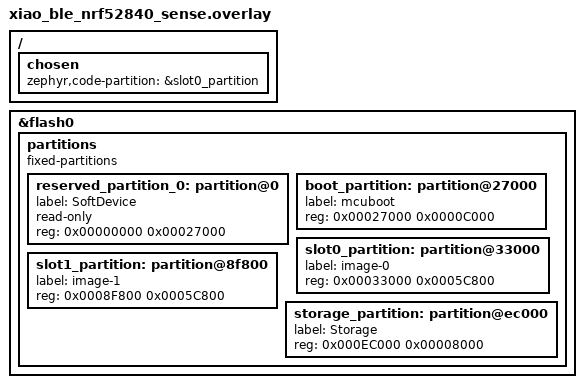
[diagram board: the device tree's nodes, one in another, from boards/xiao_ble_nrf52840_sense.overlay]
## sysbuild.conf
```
#
# Builds MCUboot as a child image so blink can be updated over BLE (OTA)
# instead of only via UF2 drag-and-drop. See apps/blink/pm_static.yml for the
# partition layout this requires.
#
SB_CONFIG_BOOTLOADER_MCUBOOT=y
```

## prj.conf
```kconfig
# Phase 0 bring-up: LED blink.
#
# Deliberately minimal — no console, no USB, no sensor drivers. If this does not
# blink, the fault is in the toolchain, the flash path or the board, not in our
# code. Console and IMU come next, one at a time.

CONFIG_GPIO=y

# Repair the hardware reset line.
#
# This board arrived with UICR->PSELRESET unconfigured, which makes the RST
# button inert: 90 s of double-tapping produced no USB re-enumeration at all.
# Without a working RST there is no way back into the UF2 bootloader, because
# Zephyr's CDC does not implement the 1200-baud touch that the previous
# (Arduino/CircuitPython) firmware did.
#
# With this set, modules/hal/nordic/nrfx/mdk/system_nrf52.c (~line 344) checks
# PSELRESET[0]/[1] at boot, and if they are not Connected writes RESET_PIN to
# both and issues NVIC_SystemReset(). The write is guarded, so it happens once
# and is a no-op on every later boot.
#
# Kconfig is marked DEPRECATED in favour of `&uicr { gpio-as-nreset; }`, which
# this board's DTS already has — but that did not translate into the generated
# .config on NCS v3.1.1, and the built hex contained no UICR segment. The
# deprecated symbol is the mechanism that demonstrably works here, so it is
# used deliberately. Expect a deprecation warning at build time.
CONFIG_GPIO_AS_PINRESET=y

# BLE OTA. NCS's own fragment (the same one Nordic's Thingy:53 DFU sample
# uses) - selects MCUmgr, the image manager and flash map for us rather than
# hand-assembling those. See apps/blink/sysbuild.conf for the MCUboot side and
# apps/blink/boards/xiao_ble_nrf52840_sense.overlay for the partition layout
# both of this depend on.
#
# The fragment only *depends on* BT_PERIPHERAL, it does not select it - a
# first attempt without these two lines built clean but silently produced a
# non-BLE blink (Kconfig warned "assigned 'y' but got 'n'": unsatisfied
# BT_PERIPHERAL dependency), so they are required, not redundant.
CONFIG_BT=y
CONFIG_BT_PERIPHERAL=y
CONFIG_NCS_SAMPLE_MCUMGR_BT_OTA_DFU=y
CONFIG_BT_DEVICE_NAME="falldetect-blink"
```

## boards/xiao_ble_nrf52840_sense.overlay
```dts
/*
 * BLE OTA layout: splits the board's stock 788 KB "Application" partition
 * (zephyr/dts/vendor/nordic/nrf52840_partition_uf2_sdv7.dtsi, included by
 * zephyr/boards/seeed/xiao_ble/xiao_ble_common.dtsi) into MCUboot + two
 * update slots.
 *
 * The three regions the Adafruit UF2 bootloader itself owns - SoftDevice
 * (0x0-0x27000), Storage (0xec000-0xf4000), and its own code at the top of
 * flash (0xf4000-0x100000, previously labelled "boot_partition"/"UF2" in the
 * stock dtsi) - keep their stock addresses and sizes, and are simply left
 * out of this partitions node. Nothing here writes to that top-of-flash
 * region, so double-tap-RST UF2 recovery still works for this entire span
 * even if a bad OTA image is ever written to slot0/slot1.
 *
 * Must stay identical to sysbuild/mcuboot.overlay - that file gives MCUboot
 * itself the same view of these partitions; this one gives it to the app.
 *
 * Math (hand-verified, fills the stock 0x27000-0xec000 span exactly):
 *   0x27000-0x33000  boot_partition   MCUboot itself       48 KB
 *   0x33000-0x8f800  slot0_partition  primary app slot    370 KB
 *   0x8f800-0xec000  slot1_partition  secondary/OTA slot  370 KB
 */

&flash0 {
	/delete-node/ partitions;

	partitions {
		compatible = "fixed-partitions";
		#address-cells = <1>;
		#size-cells = <1>;

		reserved_partition_0: partition@0 {
			label = "SoftDevice";
			read-only;
			reg = <0x00000000 0x00027000>;
		};

		boot_partition: partition@27000 {
			label = "mcuboot";
			reg = <0x00027000 0x0000C000>;
		};

		slot0_partition: partition@33000 {
			label = "image-0";
			reg = <0x00033000 0x0005C800>;
		};

		slot1_partition: partition@8f800 {
			label = "image-1";
			reg = <0x0008F800 0x0005C800>;
		};

		storage_partition: partition@ec000 {
			label = "Storage";
			reg = <0x000EC000 0x00008000>;
		};
	};
};

/*
 * Set directly for the same reason as sysbuild/mcuboot.overlay: the board's
 * stock chosen node points at the code_partition label this overlay just
 * deleted. The app runs from slot0, not from boot_partition (that's MCUboot's).
 */
/ {
	chosen {
		zephyr,code-partition = &slot0_partition;
	};
};
```

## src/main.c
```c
/*
 * Phase 0 bring-up: LED blink.
 *
 * Purpose: prove the toolchain, flash path and runtime on the XIAO nRF52840
 * Sense before any peripheral work begins. Nothing here is part of the fall
 * detector; it exists so that a later failure can be attributed to the code
 * under test rather than to the build environment.
 *
 * Execution context: LED loop runs on main thread only. BLE OTA (added on top
 * of the original blink-only scope) brings in the Bluetooth host's own
 * context for connected()/bt_ready() - both only ever call k_work_submit(),
 * never touch the LEDs or block, so the two contexts never share state.
 *
 * Board facts (Verified against
 * zephyr/boards/seeed/xiao_ble/xiao_ble_common.dtsi):
 *   led0 = Red   P0.26, active-low
 *   led1 = Green P0.30, active-low
 *   led2 = Blue  P0.06, active-low
 *
 * The active-low polarity is carried by the devicetree GPIO flags, so
 * gpio_pin_set_dt()/gpio_pin_toggle_dt() take logical levels here: "1" means
 * lit. Do not open-code the inversion.
 *
 * All three channels sit in one RGB package, so driving them together reads as
 * white. It will not be a neutral white: the three dies have different forward
 * voltages behind fixed series resistors, so expect a blue/violet cast.
 * Balancing the channels needs PWM duty control, not plain GPIO.
 */

#include <zephyr/kernel.h>
#include <zephyr/drivers/gpio.h>
#include <zephyr/bluetooth/bluetooth.h>
#include <zephyr/bluetooth/conn.h>
#include <zephyr/bluetooth/hci.h>
#include <zephyr/mgmt/mcumgr/transport/smp_bt.h>
#include <zephyr/dfu/mcuboot.h>

#define BLINK_PERIOD_MS 500U

/*
 * BLE OTA advertising. Enabling CONFIG_BT_PERIPHERAL and the MCUmgr BT
 * transport (apps/blink/prj.conf) only compiles the SMP GATT service in -
 * nothing calls bt_enable()/bt_le_adv_start() on its own, so without this the
 * radio never turns on. Pattern matches Zephyr's own reference
 * (samples/subsys/mgmt/mcumgr/smp_svr/src/bluetooth.c) rather than
 * hand-rolled advertising params.
 *
 * Execution context: bt_ready()/connected()/disconnected() run on the
 * Bluetooth host's own context, not main thread; advertise() is deferred onto
 * the system workqueue via k_work so nothing blocking happens in those
 * callbacks.
 */
static struct k_work advertise_work;

static const struct bt_data ad[] = {
	BT_DATA_BYTES(BT_DATA_FLAGS, (BT_LE_AD_GENERAL | BT_LE_AD_NO_BREDR)),
	BT_DATA_BYTES(BT_DATA_UUID128_ALL, SMP_BT_SVC_UUID_VAL),
};

static const struct bt_data sd[] = {
	BT_DATA(BT_DATA_NAME_COMPLETE, CONFIG_BT_DEVICE_NAME, sizeof(CONFIG_BT_DEVICE_NAME) - 1),
};

static void advertise(struct k_work *work)
{
	ARG_UNUSED(work);

	(void)bt_le_adv_start(BT_LE_ADV_CONN_FAST_1, ad, ARRAY_SIZE(ad), sd, ARRAY_SIZE(sd));
}

static void connected(struct bt_conn *conn, uint8_t err)
{
	ARG_UNUSED(conn);

	if (err != 0) {
		k_work_submit(&advertise_work);
	}
}

static void on_conn_recycled(void)
{
	k_work_submit(&advertise_work);
}

BT_CONN_CB_DEFINE(conn_callbacks) = {
	.connected = connected,
	.recycled = on_conn_recycled,
};

static void bt_ready(int err)
{
	if (err == 0) {
		k_work_submit(&advertise_work);
	}
}

static const struct gpio_dt_spec leds[] = {
	GPIO_DT_SPEC_GET(DT_ALIAS(led0), gpios), /* Red   */
	GPIO_DT_SPEC_GET(DT_ALIAS(led1), gpios), /* Green */
	GPIO_DT_SPEC_GET(DT_ALIAS(led2), gpios), /* Blue  */
};

int main(void)
{
	int err;
	bool lit = false;

	k_work_init(&advertise_work, advertise);
	err = bt_enable(bt_ready);
	if (err != 0) {
		return err;
	}

	for (size_t i = 0; i < ARRAY_SIZE(leds); i++) {
		if (!gpio_is_ready_dt(&leds[i])) {
			/* GPIO controller not ready: nothing further is meaningful. */
			return -ENODEV;
		}

		/* Start dark, so the first transition is visibly a change. */
		err = gpio_pin_configure_dt(&leds[i], GPIO_OUTPUT_INACTIVE);
		if (err != 0) {
			return err;
		}
	}

	/*
	 * MCUboot reverts to the previous image on the NEXT reset unless the
	 * running one explicitly confirms itself - a forgotten manual confirm
	 * from the OTA client would otherwise silently undo every update.
	 * Gated behind the LED init above passing, not called unconditionally
	 * at the top: a build that cannot even do that stays reachable over
	 * BLE to receive a fix, but still reverts if power-cycled meanwhile.
	 */
	if (!boot_is_img_confirmed()) {
		(void)boot_write_img_confirmed();
	}

	while (1) {
		lit = !lit;

		/*
		 * Drive all three from one state variable rather than toggling
		 * each independently: the channels then cannot drift out of
		 * step, which would show up as a colour tint instead of white.
		 */
		for (size_t i = 0; i < ARRAY_SIZE(leds); i++) {
			err = gpio_pin_set_dt(&leds[i], lit);
			if (err != 0) {
				return err;
			}
		}

		k_msleep(BLINK_PERIOD_MS);
	}

	return 0;
}
```
